AUTOSAR XML (schema 00044)
package /ComponentTypes
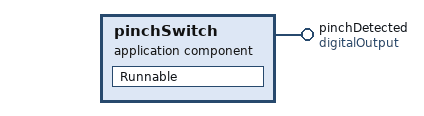
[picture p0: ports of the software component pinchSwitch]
  application sw component type pinchSwitch
    provide port pinchDetected: nonqueued-sender-com-spec=outputStatus, provided-interface=digitalOutput
    behavior pinchSwitch_InternalBehavior: supports-multiple-instantiation=true
      runnable Runnable
  swc implementation pinchSwitch_Implementation: behavior=pinchSwitch_InternalBehavior
